# nrf54l15_enga_application register map
Vendor: Nordic Semiconductor; Series: nrf54l; File version: 1
CPU: CM33 r0p4, little endian, MPU, FPU, 3 interrupt priority bits, 270 interrupts, 4 SAU regions
Registers are 32-bit, read-write, reset 0x0 unless marked. A register's access mark holds for its fields unless they carry their own. Offsets are from the block's base; [hi:lo] are bit positions; lines under a group give offsets from that group; {n}, {i} and the like mark numbered series; 'fields as' and 'values as' point back to an identical list.

## GLOBAL_ECB00_NS — AES ECB Mode Encryption 0
Base 0x40047000
Same registers: GLOBAL_ECB00_S 0x50047000
0x00 TASKS_START wo — Start ECB block encrypt
  [0] TASKS_START
    1=Trigger task
0x04 TASKS_STOP wo — Abort a possible executing ECB operation
  [0] TASKS_STOP
    1=Trigger task
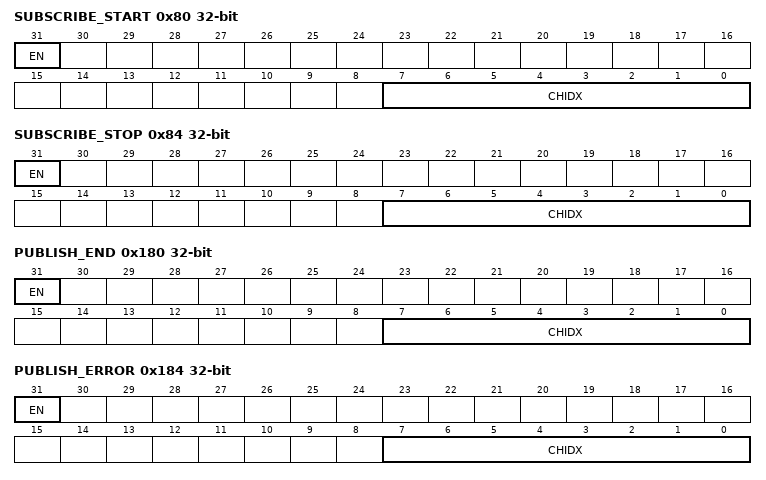
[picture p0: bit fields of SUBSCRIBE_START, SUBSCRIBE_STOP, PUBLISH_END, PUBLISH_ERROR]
0x80 SUBSCRIBE_START — Subscribe configuration for task START
  [31] EN
    0=Disabled (Disable subscription); 1=Enabled (Enable subscription)
  [7:0] CHIDX — DPPI channel that task START will subscribe to
0x84 SUBSCRIBE_STOP — Subscribe configuration for task STOP
  [31] EN
    values as SUBSCRIBE_START.EN
  [7:0] CHIDX — DPPI channel that task STOP will subscribe to
0x100 EVENTS_END — ECB block encrypt complete
  [0] EVENTS_END
    0=NotGenerated (Event not generated); 1=Generated (Event generated)
0x104 EVENTS_ERROR — ECB block encrypt aborted because of a STOP task or due to an error
  [0] EVENTS_ERROR
    values as EVENTS_END.EVENTS_END
0x180 PUBLISH_END — Publish configuration for event END
  [31] EN
    0=Disabled (Disable publishing); 1=Enabled (Enable publishing)
  [7:0] CHIDX — DPPI channel that event END will publish to
0x184 PUBLISH_ERROR — Publish configuration for event ERROR
  [31] EN
    values as PUBLISH_END.EN
  [7:0] CHIDX — DPPI channel that event ERROR will publish to
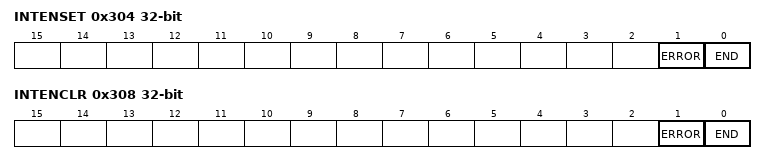
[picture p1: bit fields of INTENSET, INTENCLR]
0x304 INTENSET — Enable interrupt
  [1] ERROR — Write '1' to enable interrupt for event ERROR
    on read: 0=Disabled (Read: Disabled); 1=Enabled (Read: Enabled) | on write: 1=Set (Enable)
  [0] END — Write '1' to enable interrupt for event END
    values as ERROR
0x308 INTENCLR — Disable interrupt
  [1] ERROR — Write '1' to disable interrupt for event ERROR
    on read: 0=Disabled (Read: Disabled); 1=Enabled (Read: Enabled) | on write: 1=Clear (Disable)
  [0] END — Write '1' to disable interrupt for event END
    values as ERROR
0x400 ERRORSTATUS ro
  [2:0] ERRORSTATUS — Error status when the ERROR event is generated
    0=No errors have occurred; 1=PrematureInptrEnd (End of INPTR job list before data structure was read.); 2=PrematureOutptrEnd (End of OUTPTR job list before data structure was read.); 3=EncryptionTooSlow (Encryption of the unencrypted data structure did not complete in time.); 4=DmaError (Bus error during DMA access.)
0x510 KEY group — Unspecified
  {0x0+4j} VALUE[{j}] (j=0..3) wo — Description collection: 128-bit AES key
    [31:0] VALUE — AES 128-bit key value, bits (32*(n+1))-1 : (32*n)
0x530 IN group — IN EasyDMA channel
  0x00 PTR — Input pointer
    [31:0] PTR — Points to a job list containing unencrypted ECB data structure
0x538 OUT group — OUT EasyDMA channel
  0x00 PTR — Output pointer Points to a job list containing encrypted ECB data structure
    [31:0] PTR — Output pointer
0x53C CSAA group — Channel sounding access address scoring algorithm
  0x00 INITIATOR ro — Selected initiator for Channel Sounding Access Address
    [31:0] PN
  0x04 REFLECTOR ro — Selected initiator for Channel Sounding Access Address
    [31:0] PN
  0x08 MODE — Operation modes
    [0] BITREVERSE — Reverse the endianness on bit level for the ECB output, INITIATOR, and REFLECTOR registers
      0=Default endianness; 1=Reversed endianness

## GLOBAL_ECB10_NS — AES ECB Mode Encryption 0
Base 0x40089000
Same registers: GLOBAL_ECB10_S 0x50089000
Registers as GLOBAL_ECB00_NS; these are added or differ:
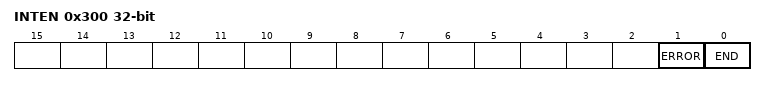
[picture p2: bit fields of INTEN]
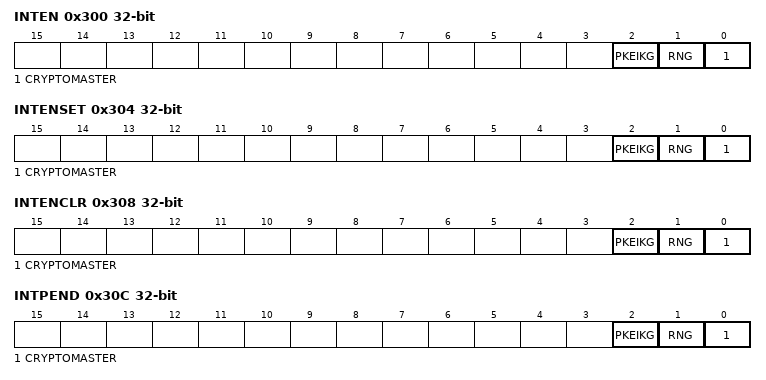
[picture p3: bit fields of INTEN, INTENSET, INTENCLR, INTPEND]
0x300 INTEN — Enable or disable interrupt
  [1] ERROR — Enable or disable interrupt for event ERROR
    0=Disabled; 1=Enabled
  [0] END — Enable or disable interrupt for event END
    0=Disabled; 1=Enabled

## GLOBAL_CRACEN_S — CRACEN
Base 0x50048000
0x100 EVENTS_CRYPTOMASTER — Event indicating that interrupt triggered at Cryptomaster
  [0] EVENTS_CRYPTOMASTER
    0=NotGenerated (Event not generated); 1=Generated (Event generated)
0x104 EVENTS_RNG — Event indicating that interrupt triggered at RNG
  [0] EVENTS_RNG
    values as EVENTS_CRYPTOMASTER.EVENTS_CRYPTOMASTER
0x108 EVENTS_PKEIKG — Event indicating that interrupt triggered at PKE or IKG
  [0] EVENTS_PKEIKG
    values as EVENTS_CRYPTOMASTER.EVENTS_CRYPTOMASTER
0x300 INTEN — Enable or disable interrupt
  [all] fields
    0=Disabled; 1=Enabled
  [2] PKEIKG — Enable or disable interrupt for event PKEIKG
  [1] RNG — Enable or disable interrupt for event RNG
  [0] CRYPTOMASTER — Enable or disable interrupt for event CRYPTOMASTER
0x304 INTENSET — Enable interrupt
  [all] fields
    on read: 0=Disabled (Read: Disabled); 1=Enabled (Read: Enabled) | on write: 1=Set (Enable)
  [2] PKEIKG — Write '1' to enable interrupt for event PKEIKG
  [1] RNG — Write '1' to enable interrupt for event RNG
  [0] CRYPTOMASTER — Write '1' to enable interrupt for event CRYPTOMASTER
0x308 INTENCLR — Disable interrupt
  [all] fields
    on read: 0=Disabled (Read: Disabled); 1=Enabled (Read: Enabled) | on write: 1=Clear (Disable)
  [2] PKEIKG — Write '1' to disable interrupt for event PKEIKG
  [1] RNG — Write '1' to disable interrupt for event RNG
  [0] CRYPTOMASTER — Write '1' to disable interrupt for event CRYPTOMASTER
0x30C INTPEND ro — Pending interrupts
  [all] fields
    on read: 0=NotPending (Read: Not pending); 1=Pending (Read: Pending)
  [2] PKEIKG — Read pending status of interrupt for event PKEIKG
  [1] RNG — Read pending status of interrupt for event RNG
  [0] CRYPTOMASTER — Read pending status of interrupt for event CRYPTOMASTER
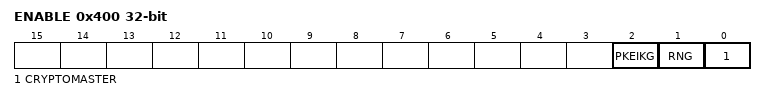
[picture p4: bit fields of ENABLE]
0x400 ENABLE — Enable CRACEN peripheral modules.
  [2] PKEIKG — Enable PKE and IKG
    0=Disabled (PKE and IKG disabled.); 1=Enabled (PKE and IKG enabled.)
  [1] RNG — Enable RNG
    0=Disabled (RNG disabled.); 1=Enabled (RNG enabled.)
  [0] CRYPTOMASTER — Enable cryptomaster
    0=Disabled (Cryptomaster disabled.); 1=Enabled (Cryptomaster enabled.)
0x404 PROTECTEDRAMLOCK — Lock the access to the protected RAM.
  [0] ENABLE — Enable the lock
    0=Disabled (Lock disabled.); 1=Enabled (Lock enabled.)
0x404 SEEDRAMLOCK (alternate view of PROTECTEDRAMLOCK) — Lock the access to the RAM used for the seed.
  fields as PROTECTEDRAMLOCK
{0x408+4i} SEED[{i}] (i=0..11) wo — Description collection: Seed word [n] for symmetric and asymmetric key generation. This register is only writable from KMU.
  [31:0] VAL — Seed value
